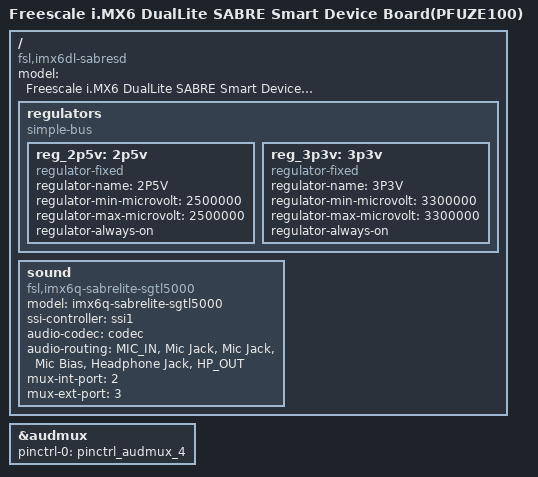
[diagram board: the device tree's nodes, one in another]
/*
 * Copyright (C) 2013-2014 Freescale Semiconductor, Inc.
 *
 * This program is free software; you can redistribute it and/or modify
 * it under the terms of the GNU General Public License version 2 as
 * published by the Free Software Foundation.
 */

/dts-v1/;

#include "imx6dl.dtsi"
#include "imx6qdl-sabresd.dtsi"
#include "imx6dl-sabresd-common.dtsi"

/ {
	model = "Freescale i.MX6 DualLite SABRE Smart Device Board(PFUZE100)";
	compatible = "fsl,imx6dl-sabresd", "fsl,imx6dl";

	regulators {
                compatible = "simple-bus";

                reg_2p5v: 2p5v {
                        compatible = "regulator-fixed";
                        regulator-name = "2P5V";
                        regulator-min-microvolt = <2500000>;
                        regulator-max-microvolt = <2500000>;
                        regulator-always-on;
                };

                reg_3p3v: 3p3v {
                        compatible = "regulator-fixed";
                        regulator-name = "3P3V";
                        regulator-min-microvolt = <3300000>;
                        regulator-max-microvolt = <3300000>;
                        regulator-always-on;
                };
        };

	sound {
                compatible = "fsl,imx6q-sabrelite-sgtl5000",
                             "fsl,imx-audio-sgtl5000";
                model = "imx6q-sabrelite-sgtl5000";
                ssi-controller = <&ssi1>;
                audio-codec = <&codec>;
                audio-routing =
                        "MIC_IN", "Mic Jack",
                        "Mic Jack", "Mic Bias",
                        "Headphone Jack", "HP_OUT";
                mux-int-port = <2>;
                mux-ext-port = <3>;
        };
};


&audmux {
        status = "okay";
        pinctrl-names = "default";
        pinctrl-0 = <&pinctrl_audmux_4>;
};

